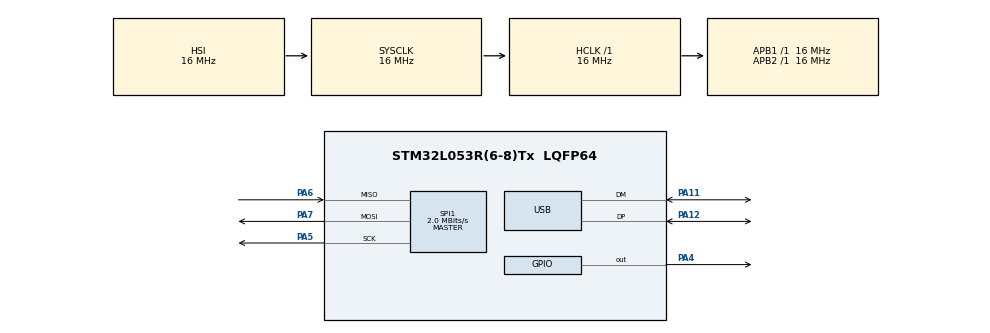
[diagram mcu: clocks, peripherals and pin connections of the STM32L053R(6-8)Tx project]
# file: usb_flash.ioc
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Mcu.Family=STM32L0
Mcu.Name=STM32L053R(6-8)Tx
Mcu.Package=LQFP64
NVIC.USB_IRQn=true\:0\:0\:false\:false\:true\:false\:true
PA11.Mode=Device
PA11.Signal=USB_DM
PA12.Mode=Device
PA12.Signal=USB_DP
PA4.GPIO_Speed=GPIO_SPEED_FREQ_HIGH
PA4.PinState=GPIO_PIN_RESET
PA4.Signal=GPIO_Output
PA5.Mode=Full_Duplex_Master
PA5.Signal=SPI1_SCK
PA6.Mode=Full_Duplex_Master
PA6.Signal=SPI1_MISO
PA7.Mode=Full_Duplex_Master
PA7.Signal=SPI1_MOSI
ProjectManager.HeapSize=0x200
ProjectManager.StackSize=0x400
ProjectManager.TargetToolchain=STM32CubeIDE
RCC.AHBFreq_Value=16000000
RCC.APB1Freq_Value=16000000
RCC.APB1TimFreq_Value=16000000
RCC.APB2Freq_Value=16000000
RCC.APB2TimFreq_Value=16000000
RCC.HCLKFreq_Value=16000000
RCC.HSE_VALUE=8000000
RCC.HSI16_VALUE=16000000
RCC.HSI48MClockSelection=RCC_USBCLKSOURCE_HSI48
RCC.HSI48_VALUE=48000000
RCC.HSI_VALUE=16000000
RCC.LSE_VALUE=32768
RCC.MSI_VALUE=2097000
RCC.SYSCLKFreq_VALUE=16000000
RCC.SYSCLKSource=RCC_SYSCLKSOURCE_HSI
RCC.VCOOutputFreq_Value=48000000
SPI1.BaudRatePrescaler=SPI_BAUDRATEPRESCALER_8
SPI1.CLKPhase=SPI_PHASE_1EDGE
SPI1.CLKPolarity=SPI_POLARITY_LOW
SPI1.CalculateBaudRate=2.0 MBits/s
SPI1.Direction=SPI_DIRECTION_2LINES
SPI1.Mode=SPI_MODE_MASTER
SPI1.VirtualType=VM_MASTER
USB_DEVICE.CLASS_NAME_FS=MSC
USB_DEVICE.VirtualMode=Msc
USB_DEVICE.VirtualModeFS=Msc_FS
VP_USB_DEVICE_VS_USB_DEVICE_MSC_FS.Mode=MSC_FS
board=custom

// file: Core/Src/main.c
/* USER CODE BEGIN Header */
/**
  ******************************************************************************
  * @file           : main.c
  * @brief          : Main program body
  ******************************************************************************
  * @attention
  *
  * <h2><center>&copy; Copyright (c) 2021 STMicroelectronics.
  * All rights reserved.</center></h2>
  *
  * This software component is licensed by ST under BSD 3-Clause license,
  * the "License"; You may not use this file except in compliance with the
  * License. You may obtain a copy of the License at:
  *                        opensource.org/licenses/BSD-3-Clause
  *
  ******************************************************************************
  */
/* USER CODE END Header */
#include "main.h"
#include "usb_device.h"

/* USER CODE BEGIN Includes */
#include "w25qxx.h"
extern uint32_t	id;
/* USER CODE END Includes */

SPI_HandleTypeDef hspi1;

void SystemClock_Config(void);
static void MX_GPIO_Init(void);
static void MX_SPI1_Init(void);
/* USER CODE BEGIN PFP */

//############################################################################
                // buffer to read the data from the USB file and store it in config_wr_buffer //
//############################################################################

uint8_t config_wr_Buffer[76] = "ST,15:14:14 8 21,ET,STX,30,10,5,20,10,5,30,10,5,20,10,5,30,10,5,20,10,8,ETX";

//############################################################################
                // config_rec_buffer - buffer to read the data from the flash chip //
//############################################################################

uint8_t config_rec_Buffer[76];

/* USER CODE END PFP */

int main(void)
{

  /* MCU Configuration--------------------------------------------------------*/

  /* Reset of all peripherals, Initializes the Flash interface and the Systick. */
  HAL_Init();

  /* Configure the system clock */
  SystemClock_Config();

  /* Initialize all configured peripherals */
  MX_GPIO_Init();
  MX_SPI1_Init();
  MX_USB_DEVICE_Init();

  /* USER CODE BEGIN 2 */

  W25qxx_Init();
  W25qxx_EraseChip();
  //W25qxx_EraseBlock(1);
  HAL_Delay(1000);
  W25qxx_WritePage(&config_wr_Buffer[0], 1, 0,  76);
  HAL_Delay(50);
  W25qxx_ReadPage(&config_rec_Buffer[0], 1, 0, 76);

  /* USER CODE END 2 */

  /* Infinite loop */
  while (1)
  {

  }
}

void SystemClock_Config(void)
{
  RCC_OscInitTypeDef RCC_OscInitStruct = {0};
  RCC_ClkInitTypeDef RCC_ClkInitStruct = {0};
  RCC_PeriphCLKInitTypeDef PeriphClkInit = {0};

  /** Configure the main internal regulator output voltage
  */
  __HAL_PWR_VOLTAGESCALING_CONFIG(PWR_REGULATOR_VOLTAGE_SCALE1);
  /** Initializes the RCC Oscillators according to the specified parameters
  * in the RCC_OscInitTypeDef structure.
  */
  RCC_OscInitStruct.OscillatorType = RCC_OSCILLATORTYPE_HSI|RCC_OSCILLATORTYPE_HSI48;
  RCC_OscInitStruct.HSIState = RCC_HSI_ON;
  RCC_OscInitStruct.HSICalibrationValue = RCC_HSICALIBRATION_DEFAULT;
  RCC_OscInitStruct.HSI48State = RCC_HSI48_ON;
  RCC_OscInitStruct.PLL.PLLState = RCC_PLL_NONE;
  if (HAL_RCC_OscConfig(&RCC_OscInitStruct) != HAL_OK)
  {
    Error_Handler();
  }
  /** Initializes the CPU, AHB and APB buses clocks
  */
  RCC_ClkInitStruct.ClockType = RCC_CLOCKTYPE_HCLK|RCC_CLOCKTYPE_SYSCLK
                              |RCC_CLOCKTYPE_PCLK1|RCC_CLOCKTYPE_PCLK2;
  RCC_ClkInitStruct.SYSCLKSource = RCC_SYSCLKSOURCE_HSI;
  RCC_ClkInitStruct.AHBCLKDivider = RCC_SYSCLK_DIV1;
  RCC_ClkInitStruct.APB1CLKDivider = RCC_HCLK_DIV1;
  RCC_ClkInitStruct.APB2CLKDivider = RCC_HCLK_DIV1;

  if (HAL_RCC_ClockConfig(&RCC_ClkInitStruct, FLASH_LATENCY_0) != HAL_OK)
  {
    Error_Handler();
  }
  PeriphClkInit.PeriphClockSelection = RCC_PERIPHCLK_USB;
  PeriphClkInit.UsbClockSelection = RCC_USBCLKSOURCE_HSI48;
  if (HAL_RCCEx_PeriphCLKConfig(&PeriphClkInit) != HAL_OK)
  {
    Error_Handler();
  }
}

static void MX_SPI1_Init(void)
{

  /* SPI1 parameter configuration*/
  hspi1.Instance = SPI1;
  hspi1.Init.Mode = SPI_MODE_MASTER;
  hspi1.Init.Direction = SPI_DIRECTION_2LINES;
  hspi1.Init.DataSize = SPI_DATASIZE_8BIT;
  hspi1.Init.CLKPolarity = SPI_POLARITY_LOW;
  hspi1.Init.CLKPhase = SPI_PHASE_1EDGE;
  hspi1.Init.NSS = SPI_NSS_SOFT;
  hspi1.Init.BaudRatePrescaler = SPI_BAUDRATEPRESCALER_8;
  hspi1.Init.FirstBit = SPI_FIRSTBIT_MSB;
  hspi1.Init.TIMode = SPI_TIMODE_DISABLE;
  hspi1.Init.CRCCalculation = SPI_CRCCALCULATION_DISABLE;
  hspi1.Init.CRCPolynomial = 7;
  if (HAL_SPI_Init(&hspi1) != HAL_OK)
  {
    Error_Handler();
  }

}

static void MX_GPIO_Init(void)
{
  GPIO_InitTypeDef GPIO_InitStruct = {0};

  /* GPIO Ports Clock Enable */
  __HAL_RCC_GPIOA_CLK_ENABLE();

  /*Configure GPIO pin Output Level */
  HAL_GPIO_WritePin(GPIOA, GPIO_PIN_4, GPIO_PIN_RESET);

  /*Configure GPIO pin : PA4 */
  GPIO_InitStruct.Pin = GPIO_PIN_4;
  GPIO_InitStruct.Mode = GPIO_MODE_OUTPUT_PP;
  GPIO_InitStruct.Pull = GPIO_NOPULL;
  GPIO_InitStruct.Speed = GPIO_SPEED_FREQ_MEDIUM;
  HAL_GPIO_Init(GPIOA, &GPIO_InitStruct);

}

void Error_Handler(void)
{
  __disable_irq();
  while (1)
  {
  }
}

/************************ (C) COPYRIGHT STMicroelectronics *****END OF FILE****/
